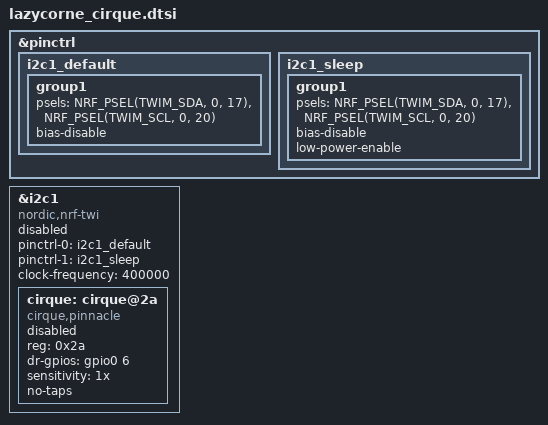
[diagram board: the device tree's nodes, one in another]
// #define INPUT_EV_KEY 0x01               /**< Key event */
// #define INPUT_EV_REL 0x02               /**< Relative coordinate event */
// #define INPUT_EV_ABS 0x03               /**< Absolute coordinate event */
// #define INPUT_EV_MSC 0x04               /**< Miscellaneous event */
// #define INPUT_EV_VENDOR_START 0xf0      /**< Vendor specific event start */
// #define INPUT_EV_VENDOR_STOP 0xff       /**< Vendor specific event stop */
//
// #define INPUT_REL_X 0x00                /**< Relative X coordinate */
// #define INPUT_REL_Y 0x01                /**< Relative Y coordinate */
// #define INPUT_REL_WHEEL 0x08            /**< Relative wheel coordinate */
// #define INPUT_REL_HWHEEL 0x06           /**< Relative horizontal wheel coordinate */
// #define INPUT_REL_MISC 0x09             /**< Relative misc coordinate */


// 만약 풀업저항이 물리적으로 장착되지 않았다면 소프트웨어적으로 처리할 수 있음
&pinctrl {
  i2c1_default:i2c1_default {
    group1 {
      psels = <NRF_PSEL(TWIM_SDA, 0, 17)>,
          <NRF_PSEL(TWIM_SCL, 0, 20)>;
      bias-disable;
      // bias-pull-up;
    };
  };
  i2c1_sleep:i2c1_sleep {
    group1 {
      psels = <NRF_PSEL(TWIM_SDA, 0, 17)>,
          <NRF_PSEL(TWIM_SCL, 0, 20)>;
      bias-disable;
      // bias-pull-up;
      low-power-enable;
    };
  };

};

&i2c1{
    status="disabled";
    compatible = "nordic,nrf-twi";
    pinctrl-0 = <&i2c1_default>;
    pinctrl-1 = <&i2c1_sleep>;
    pinctrl-names = "default", "sleep";
    clock-frequency = < 400000 >;
    cirque: cirque@2a {
        compatible = "cirque,pinnacle";
        reg = <0x2a>;
        status = "disabled";
        dr-gpios = <&gpio0 6 (GPIO_ACTIVE_HIGH)>;
        sensitivity = "1x";
        // sleep;
        no-taps;
    };
};


// &pro_micro_i2c {
//     status = "disabled";
//     clock-frequency = < 400000 >;
//     cirque: cirque@2a {
//         compatible = "cirque,pinnacle";
//         reg = <0x2a>;
//         status = "disabled";
//         dr-gpios = <&gpio0 6 (GPIO_ACTIVE_HIGH)>;
//         sensitivity = "1x";
//         // sleep;
//         // no-taps;
//     };
// };
